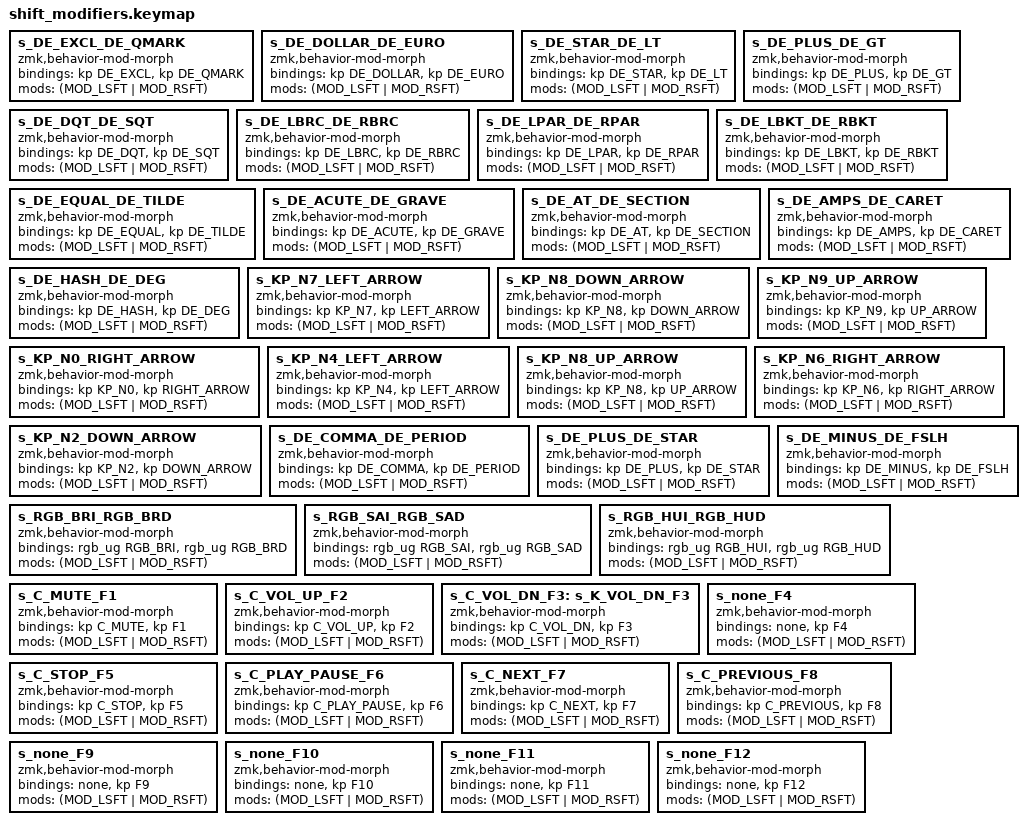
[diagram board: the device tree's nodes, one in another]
/* 
    keyoutput[default]  ¦  keyoutput[with modifer]
    s[for shift]_key[default]_key[in combination with modifer]: s[for shift]_key[default]_key[in combination with modifer]
*/

/* !  ¦  ? */
s_DE_EXCL_DE_QMARK: s_DE_EXCL_DE_QMARK {
    compatible = "zmk,behavior-mod-morph";
    #binding-cells = <0>;
    bindings = <&kp DE_EXCL>, <&kp DE_QMARK>;
    mods = <(MOD_LSFT | MOD_RSFT)>;
};
/* $  ¦  € */
s_DE_DOLLAR_DE_EURO: s_DE_DOLLAR_DE_EURO {
    compatible = "zmk,behavior-mod-morph";
    #binding-cells = <0>;
    bindings = <&kp DE_DOLLAR>, <&kp DE_EURO>;
    mods = <(MOD_LSFT | MOD_RSFT)>;
};
/* *  ¦  < */
s_DE_STAR_DE_LT: s_DE_STAR_DE_LT {
    compatible = "zmk,behavior-mod-morph";
    #binding-cells = <0>;
    bindings = <&kp DE_STAR>, <&kp DE_LT>;
    mods = <(MOD_LSFT | MOD_RSFT)>;
};
/* +  ¦  > */
s_DE_PLUS_DE_GT: s_DE_PLUS_DE_GT {
    compatible = "zmk,behavior-mod-morph";
    #binding-cells = <0>;
    bindings = <&kp DE_PLUS>, <&kp DE_GT>;
    mods = <(MOD_LSFT | MOD_RSFT)>;
};
/* "  ¦  ' */
s_DE_DQT_DE_SQT: s_DE_DQT_DE_SQT {
    compatible = "zmk,behavior-mod-morph";
    #binding-cells = <0>;
    bindings = <&kp DE_DQT>, <&kp DE_SQT>;
    mods = <(MOD_LSFT | MOD_RSFT)>;
};
/* {  ¦  } */
s_DE_LBRC_DE_RBRC: s_DE_LBRC_DE_RBRC {
    compatible = "zmk,behavior-mod-morph";
    #binding-cells = <0>;
    bindings = <&kp DE_LBRC>, <&kp DE_RBRC>;
    mods = <(MOD_LSFT | MOD_RSFT)>;
};
/* (  ¦  ) */
s_DE_LPAR_DE_RPAR: s_DE_LPAR_DE_RPAR {
    compatible = "zmk,behavior-mod-morph";
    #binding-cells = <0>;
    bindings = <&kp DE_LPAR>, <&kp DE_RPAR>;
    mods = <(MOD_LSFT | MOD_RSFT)>;
};
/* [  ¦  ] */
s_DE_LBKT_DE_RBKT: s_DE_LBKT_DE_RBKT {
    compatible = "zmk,behavior-mod-morph";
    #binding-cells = <0>;
    bindings = <&kp DE_LBKT>, <&kp DE_RBKT>;
    mods = <(MOD_LSFT | MOD_RSFT)>;
};
/* =  ¦  ~ */
s_DE_EQUAL_DE_TILDE: s_DE_EQUAL_DE_TILDE {
    compatible = "zmk,behavior-mod-morph";
    #binding-cells = <0>;
    bindings = <&kp DE_EQUAL>, <&kp DE_TILDE>;
    mods = <(MOD_LSFT | MOD_RSFT)>;
};
/* ´  ¦  ` */
s_DE_ACUTE_DE_GRAVE: s_DE_ACUTE_DE_GRAVE {
    compatible = "zmk,behavior-mod-morph";
    #binding-cells = <0>;
    bindings = <&kp DE_ACUTE>, <&kp DE_GRAVE>;
    mods = <(MOD_LSFT | MOD_RSFT)>;
};
/* @  ¦  § */
s_DE_AT_DE_SECTION: s_DE_AT_DE_SECTION {
    compatible = "zmk,behavior-mod-morph";
    #binding-cells = <0>;
    bindings = <&kp DE_AT>, <&kp DE_SECTION>;
    mods = <(MOD_LSFT | MOD_RSFT)>;
};
/* &  ¦  ^ */
s_DE_AMPS_DE_CARET: s_DE_AMPS_DE_CARET {
    compatible = "zmk,behavior-mod-morph";
    #binding-cells = <0>;
    bindings = <&kp DE_AMPS>, <&kp DE_CARET>;
    mods = <(MOD_LSFT | MOD_RSFT)>;
};
/* #  ¦  ° */
s_DE_HASH_DE_DEG: s_DE_HASH_DE_DEG {
    compatible = "zmk,behavior-mod-morph";
    #binding-cells = <0>;
    bindings = <&kp DE_HASH>, <&kp DE_DEG>;
    mods = <(MOD_LSFT | MOD_RSFT)>;
};
/* 7  ¦  ⬅ */
s_KP_N7_LEFT_ARROW: s_KP_N7_LEFT_ARROW {
    compatible = "zmk,behavior-mod-morph";
    #binding-cells = <0>;
    bindings = <&kp KP_N7>, <&kp LEFT_ARROW>;
    mods = <(MOD_LSFT | MOD_RSFT)>;
};
/* 8  ¦  ⬇ */
s_KP_N8_DOWN_ARROW: s_KP_N8_DOWN_ARROW {
    compatible = "zmk,behavior-mod-morph";
    #binding-cells = <0>;
    bindings = <&kp KP_N8>, <&kp DOWN_ARROW>;
    mods = <(MOD_LSFT | MOD_RSFT)>;
};
/* 9  ¦  ⬆ */
s_KP_N9_UP_ARROW: s_KP_N9_UP_ARROW {
    compatible = "zmk,behavior-mod-morph";
    #binding-cells = <0>;
    bindings = <&kp KP_N9>, <&kp UP_ARROW>;
    mods = <(MOD_LSFT | MOD_RSFT)>;
};
/* 0  ¦  ⮕ */
s_KP_N0_RIGHT_ARROW: s_KP_N0_RIGHT_ARROW {
    compatible = "zmk,behavior-mod-morph";
    #binding-cells = <0>;
    bindings = <&kp KP_N0>, <&kp RIGHT_ARROW>;
    mods = <(MOD_LSFT | MOD_RSFT)>;
};
/* 4  ¦  ⬅ */
s_KP_N4_LEFT_ARROW: s_KP_N4_LEFT_ARROW {
    compatible = "zmk,behavior-mod-morph";
    #binding-cells = <0>;
    bindings = <&kp KP_N4>, <&kp LEFT_ARROW>;
    mods = <(MOD_LSFT | MOD_RSFT)>;
};
/* 8  ¦  ⬆ */
s_KP_N8_UP_ARROW: s_KP_N8_UP_ARROW {
    compatible = "zmk,behavior-mod-morph";
    #binding-cells = <0>;
    bindings = <&kp KP_N8>, <&kp UP_ARROW>;
    mods = <(MOD_LSFT | MOD_RSFT)>;
};
/* 6  ¦  ⮕ */
s_KP_N6_RIGHT_ARROW: s_KP_N6_RIGHT_ARROW {
    compatible = "zmk,behavior-mod-morph";
    #binding-cells = <0>;
    bindings = <&kp KP_N6>, <&kp RIGHT_ARROW>;
    mods = <(MOD_LSFT | MOD_RSFT)>;
};
/* 2  ¦  ⬇ */
s_KP_N2_DOWN_ARROW: s_KP_N2_DOWN_ARROW {
    compatible = "zmk,behavior-mod-morph";
    #binding-cells = <0>;
    bindings = <&kp KP_N2>, <&kp DOWN_ARROW>;
    mods = <(MOD_LSFT | MOD_RSFT)>;
};
/* ,  ¦  . */
s_DE_COMMA_DE_PERIOD: s_DE_COMMA_DE_PERIOD {
    compatible = "zmk,behavior-mod-morph";
    #binding-cells = <0>;
    bindings = <&kp DE_COMMA>, <&kp DE_PERIOD>;
    mods = <(MOD_LSFT | MOD_RSFT)>;
};
/* +  ¦  * */
s_DE_PLUS_DE_STAR: s_DE_PLUS_DE_STAR {
    compatible = "zmk,behavior-mod-morph";
    #binding-cells = <0>;
    bindings = <&kp DE_PLUS>, <&kp DE_STAR>;
    mods = <(MOD_LSFT | MOD_RSFT)>;
};
/* -  ¦  / */
s_DE_MINUS_DE_FSLH: s_DE_MINUS_DE_FSLH {
    compatible = "zmk,behavior-mod-morph";
    #binding-cells = <0>;
    bindings = <&kp DE_MINUS>, <&kp DE_FSLH>;
    mods = <(MOD_LSFT | MOD_RSFT)>;
};
/* BRI  ¦  BRD */
s_RGB_BRI_RGB_BRD: s_RGB_BRI_RGB_BRD {
    compatible = "zmk,behavior-mod-morph";
    #binding-cells = <0>;
    bindings = <&rgb_ug RGB_BRI>, <&rgb_ug RGB_BRD>;
    mods = <(MOD_LSFT | MOD_RSFT)>;
};
/* SAI  ¦  SAD */
s_RGB_SAI_RGB_SAD: s_RGB_SAI_RGB_SAD {
    compatible = "zmk,behavior-mod-morph";
    #binding-cells = <0>;
    bindings = <&rgb_ug RGB_SAI>, <&rgb_ug RGB_SAD>;
    mods = <(MOD_LSFT | MOD_RSFT)>;
};
/* HUI  ¦  HUD */
s_RGB_HUI_RGB_HUD: s_RGB_HUI_RGB_HUD {
    compatible = "zmk,behavior-mod-morph";
    #binding-cells = <0>;
    bindings = <&rgb_ug RGB_HUI>, <&rgb_ug RGB_HUD>;
    mods = <(MOD_LSFT | MOD_RSFT)>;
};
/* MUTE  ¦  F1 */
s_C_MUTE_F1: s_C_MUTE_F1 {
    compatible = "zmk,behavior-mod-morph";
    #binding-cells = <0>;
    bindings = <&kp C_MUTE>, <&kp F1>;
    mods = <(MOD_LSFT | MOD_RSFT)>;
};
/* VOL UP  ¦  F2 */
s_C_VOL_UP_F2: s_C_VOL_UP_F2 {
    compatible = "zmk,behavior-mod-morph";
    #binding-cells = <0>;
    bindings = <&kp C_VOL_UP>, <&kp F2>;
    mods = <(MOD_LSFT | MOD_RSFT)>;
};
/* VOL DOWN  ¦  F3 */
s_C_VOL_DN_F3: s_K_VOL_DN_F3 {
    compatible = "zmk,behavior-mod-morph";
    #binding-cells = <0>;
    bindings = <&kp C_VOL_DN>, <&kp F3>;
    mods = <(MOD_LSFT | MOD_RSFT)>;
};
/* none  ¦  F4 */
s_none_F4: s_none_F4 {
    compatible = "zmk,behavior-mod-morph";
    #binding-cells = <0>;
    bindings = <&none>, <&kp F4>;
    mods = <(MOD_LSFT | MOD_RSFT)>;
};
/* STOP  ¦  F5 */
s_C_STOP_F5: s_C_STOP_F5 {
    compatible = "zmk,behavior-mod-morph";
    #binding-cells = <0>;
    bindings = <&kp C_STOP>, <&kp F5>;
    mods = <(MOD_LSFT | MOD_RSFT)>;
};
/* PLAY/PAUSE  ¦  F6 */
s_C_PLAY_PAUSE_F6: s_C_PLAY_PAUSE_F6 {
    compatible = "zmk,behavior-mod-morph";
    #binding-cells = <0>;
    bindings = <&kp C_PLAY_PAUSE>, <&kp F6>;
    mods = <(MOD_LSFT | MOD_RSFT)>;
};
/* NEXT  ¦  F7 */
s_C_NEXT_F7: s_C_NEXT_F7 {
    compatible = "zmk,behavior-mod-morph";
    #binding-cells = <0>;
    bindings = <&kp C_NEXT>, <&kp F7>;
    mods = <(MOD_LSFT | MOD_RSFT)>;
};
/* PREVIOUS  ¦  F8 */
s_C_PREVIOUS_F8: s_C_PREVIOUS_F8 {
    compatible = "zmk,behavior-mod-morph";
    #binding-cells = <0>;
    bindings = <&kp C_PREVIOUS>, <&kp F8>;
    mods = <(MOD_LSFT | MOD_RSFT)>;
};
/* none  ¦  F9 */
s_none_F9: s_none_F9 {
    compatible = "zmk,behavior-mod-morph";
    #binding-cells = <0>;
    bindings = <&none>, <&kp F9>;
    mods = <(MOD_LSFT | MOD_RSFT)>;
};
/* none  ¦  F10 */
s_none_F10: s_none_F10 {
    compatible = "zmk,behavior-mod-morph";
    #binding-cells = <0>;
    bindings = <&none>, <&kp F10>;
    mods = <(MOD_LSFT | MOD_RSFT)>;
};
/* none  ¦  F11 */
s_none_F11: s_none_F11 {
    compatible = "zmk,behavior-mod-morph";
    #binding-cells = <0>;
    bindings = <&none>, <&kp F11>;
    mods = <(MOD_LSFT | MOD_RSFT)>;
};
/* none  ¦  F12 */
s_none_F12: s_none_F12 {
    compatible = "zmk,behavior-mod-morph";
    #binding-cells = <0>;
    bindings = <&none>, <&kp F12>;
    mods = <(MOD_LSFT | MOD_RSFT)>;
};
